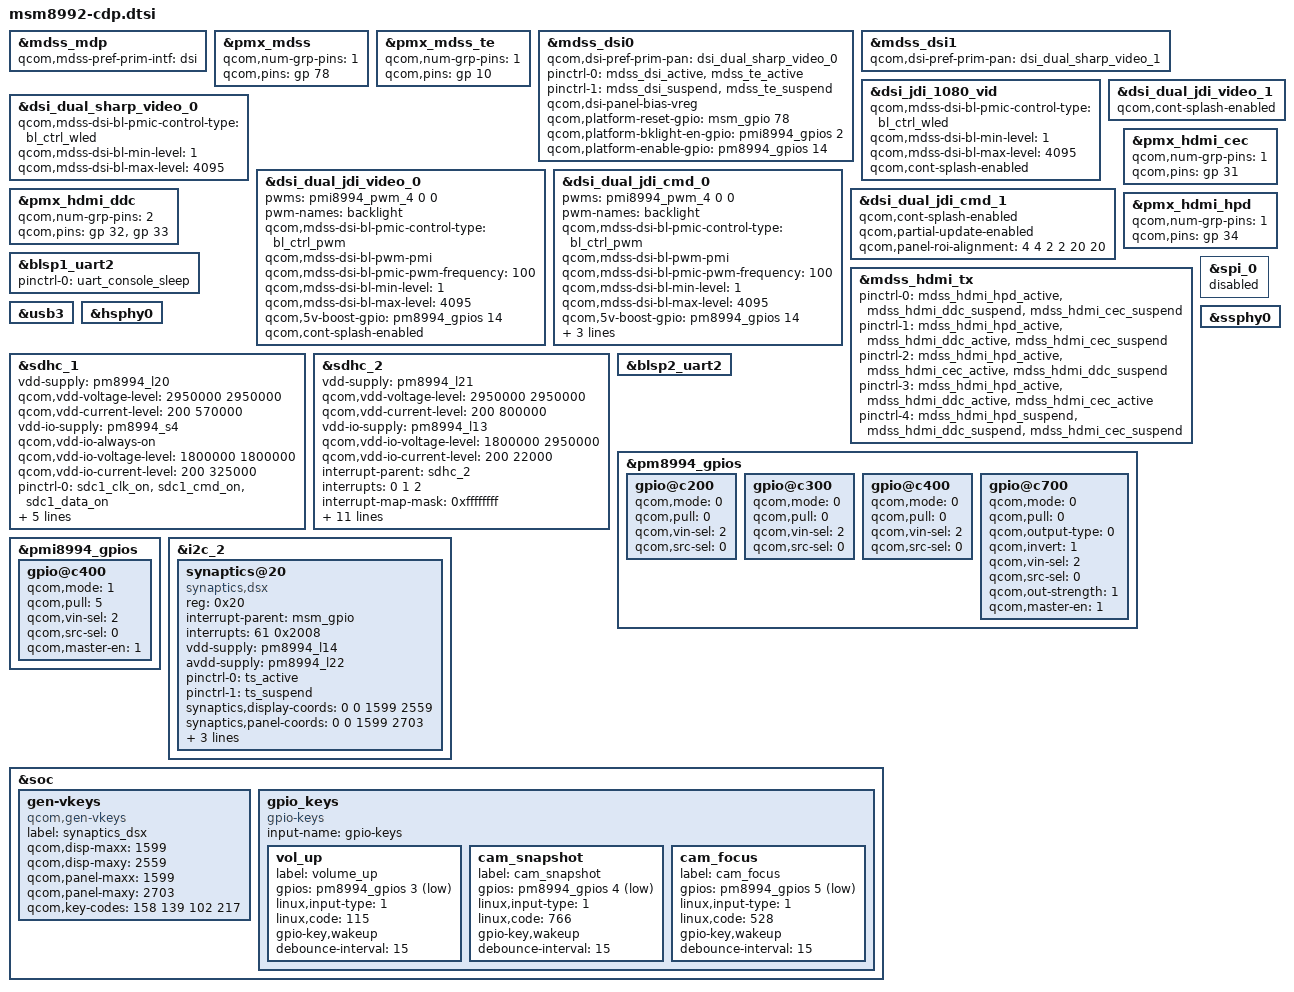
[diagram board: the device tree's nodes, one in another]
/* Copyright (c) 2014, The Linux Foundation. All rights reserved.
 *
 * This program is free software; you can redistribute it and/or modify
 * it under the terms of the GNU General Public License version 2 and
 * only version 2 as published by the Free Software Foundation.
 *
 * This program is distributed in the hope that it will be useful,
 * but WITHOUT ANY WARRANTY; without even the implied warranty of
 * MERCHANTABILITY or FITNESS FOR A PARTICULAR PURPOSE.  See the
 * GNU General Public License for more details.
 */

#include "msm8992-pinctrl.dtsi"

#include "dsi-panel-sharp-dualmipi0-wqxga-video.dtsi"
#include "dsi-panel-sharp-dualmipi1-wqxga-video.dtsi"
#include "dsi-panel-jdi-dualmipi0-video.dtsi"
#include "dsi-panel-jdi-dualmipi1-video.dtsi"
#include "dsi-panel-jdi-dualmipi0-cmd.dtsi"
#include "dsi-panel-jdi-dualmipi1-cmd.dtsi"
#include "dsi-panel-nt35597-wqxga-video.dtsi"
#include "dsi-panel-nt35597-wqxga-cmd.dtsi"
#include "dsi-panel-jdi-1080p-video.dtsi"

&mdss_mdp {
	qcom,mdss-pref-prim-intf = "dsi";
};

&pmx_mdss {
	qcom,num-grp-pins = <1>;
	qcom,pins = <&gp 78>;
};

&pmx_mdss_te {
	qcom,num-grp-pins = <1>;
	qcom,pins = <&gp 10>;
};

&mdss_dsi0 {
	qcom,dsi-pref-prim-pan = <&dsi_dual_sharp_video_0>;
	pinctrl-names = "mdss_default", "mdss_sleep";
	pinctrl-0 = <&mdss_dsi_active &mdss_te_active>;
	pinctrl-1 = <&mdss_dsi_suspend &mdss_te_suspend>;
	qcom,dsi-panel-bias-vreg;
	qcom,platform-reset-gpio = <&msm_gpio 78 0>;
	qcom,platform-bklight-en-gpio = <&pmi8994_gpios 2 0>;
	qcom,platform-enable-gpio = <&pm8994_gpios 14 0>;
};

&mdss_dsi1 {
	qcom,dsi-pref-prim-pan = <&dsi_dual_sharp_video_1>;
};

&dsi_jdi_1080_vid {
	qcom,mdss-dsi-bl-pmic-control-type = "bl_ctrl_wled";
	qcom,mdss-dsi-bl-min-level = <1>;
	qcom,mdss-dsi-bl-max-level = <4095>;
	qcom,cont-splash-enabled;
};

&dsi_dual_sharp_video_0 {
	qcom,mdss-dsi-bl-pmic-control-type = "bl_ctrl_wled";
	qcom,mdss-dsi-bl-min-level = <1>;
	qcom,mdss-dsi-bl-max-level = <4095>;
};

&dsi_dual_jdi_video_0 {
	pwms = <&pmi8994_pwm_4 0 0>;
	pwm-names = "backlight";
	qcom,mdss-dsi-bl-pmic-control-type = "bl_ctrl_pwm";
	qcom,mdss-dsi-bl-pwm-pmi;
	qcom,mdss-dsi-bl-pmic-pwm-frequency = <100>;
	qcom,mdss-dsi-bl-min-level = <1>;
	qcom,mdss-dsi-bl-max-level = <4095>;
	qcom,5v-boost-gpio = <&pm8994_gpios 14 0>;
	qcom,cont-splash-enabled;
};

&dsi_dual_jdi_video_1 {
	qcom,cont-splash-enabled;
};

&dsi_dual_jdi_cmd_0 {
	pwms = <&pmi8994_pwm_4 0 0>;
	pwm-names = "backlight";
	qcom,mdss-dsi-bl-pmic-control-type = "bl_ctrl_pwm";
	qcom,mdss-dsi-bl-pwm-pmi;
	qcom,mdss-dsi-bl-pmic-pwm-frequency = <100>;
	qcom,mdss-dsi-bl-min-level = <1>;
	qcom,mdss-dsi-bl-max-level = <4095>;
	qcom,5v-boost-gpio = <&pm8994_gpios 14 0>;
	qcom,cont-splash-enabled;
	qcom,partial-update-enabled;
	qcom,panel-roi-alignment = <4 4 2 2 20 20>;
};

&dsi_dual_jdi_cmd_1 {
	qcom,cont-splash-enabled;
	qcom,partial-update-enabled;
	qcom,panel-roi-alignment = <4 4 2 2 20 20>;
};

&pmx_hdmi_cec {
	qcom,num-grp-pins = <1>;
	qcom,pins = <&gp 31>;
};

&pmx_hdmi_ddc {
	qcom,num-grp-pins = <2>;
	qcom,pins = <&gp 32>, <&gp 33>;
};

&pmx_hdmi_hpd {
	qcom,num-grp-pins = <1>;
	qcom,pins = <&gp 34>;
};

&mdss_hdmi_tx {
	pinctrl-names = "hdmi_hpd_active", "hdmi_ddc_active",
				"hdmi_cec_active", "hdmi_active",
				"hdmi_sleep";
	pinctrl-0 = <&mdss_hdmi_hpd_active &mdss_hdmi_ddc_suspend
						&mdss_hdmi_cec_suspend>;
	pinctrl-1 = <&mdss_hdmi_hpd_active &mdss_hdmi_ddc_active
						&mdss_hdmi_cec_suspend>;
	pinctrl-2 = <&mdss_hdmi_hpd_active &mdss_hdmi_cec_active
						&mdss_hdmi_ddc_suspend>;
	pinctrl-3 = <&mdss_hdmi_hpd_active &mdss_hdmi_ddc_active
						&mdss_hdmi_cec_active>;
	pinctrl-4 = <&mdss_hdmi_hpd_suspend &mdss_hdmi_ddc_suspend
						&mdss_hdmi_cec_suspend>;
};
&blsp1_uart2 {
	status= "ok";
	pinctrl-names = "default";
	pinctrl-0 = <&uart_console_sleep>;
};

&spi_0 {
	status = "disabled";
};

&usb3 {
	status = "ok";
};

&hsphy0 {
	status = "ok";
};

&ssphy0 {
	status = "ok";
};

&sdhc_1 {
	vdd-supply = <&pm8994_l20>;
	qcom,vdd-voltage-level = <2950000 2950000>;
	qcom,vdd-current-level = <200 570000>;

	vdd-io-supply = <&pm8994_s4>;
	qcom,vdd-io-always-on;
	qcom,vdd-io-voltage-level = <1800000 1800000>;
	qcom,vdd-io-current-level = <200 325000>;

	pinctrl-names = "active", "sleep";
	pinctrl-0 = <&sdc1_clk_on &sdc1_cmd_on &sdc1_data_on>;
	pinctrl-1 = <&sdc1_clk_off &sdc1_cmd_off &sdc1_data_off>;

	qcom,clk-rates = <400000 20000000 25000000 50000000>;
	qcom,nonremovable;
	status = "ok";
};

&sdhc_2 {
	vdd-supply = <&pm8994_l21>;
	qcom,vdd-voltage-level = <2950000 2950000>;
	qcom,vdd-current-level = <200 800000>;

	vdd-io-supply = <&pm8994_l13>;
	qcom,vdd-io-voltage-level = <1800000 2950000>;
	qcom,vdd-io-current-level = <200 22000>;

	#address-cells = <0>;
	interrupt-parent = <&sdhc_2>;
	interrupts = <0 1 2>;
	#interrupt-cells = <1>;
	interrupt-map-mask = <0xffffffff>;
	interrupt-map = <0 &intc 0 125 0
			1 &intc 0 221 0
			2 &pm8994_gpios 8 0x3>;
	interrupt-names = "hc_irq", "pwr_irq", "status_irq";
	cd-gpios = <&pm8994_gpios 8 0x1>;

	pinctrl-names = "active", "sleep";
	pinctrl-0 = <&sdc2_clk_on &sdc2_cmd_on &sdc2_data_on>;
	pinctrl-1 = <&sdc2_clk_off &sdc2_cmd_off &sdc2_data_off>;

	qcom,clk-rates = <400000 20000000 25000000 50000000 100000000 200000000>;
	qcom,bus-speed-mode = "SDR12", "SDR25", "SDR50", "DDR50", "SDR104";
	status = "ok";
};

&blsp2_uart2 {
	status = "ok";
};

&pm8994_gpios {
	gpio@c200 { /* GPIO 3 */
		qcom,mode = <0>;		/* Digital in */
		qcom,pull = <0>;		/* PULL up 30uA */
		qcom,vin-sel = <2>;		/* Logical 1 voltage value 1.8v */
		qcom,src-sel = <0>;		/* Constant */
		status = "okay";
	};

	gpio@c300 { /* GPIO 4 */
		qcom,mode = <0>;		/* Digital in */
		qcom,pull = <0>;		/* PULL up 30uA */
		qcom,vin-sel = <2>;		/* Logical 1 voltage value 1.8v */
		qcom,src-sel = <0>;		/* Constant */
		status = "okay";
	};

	gpio@c400 { /* GPIO 5 */
		qcom,mode = <0>;		/* Digital in */
		qcom,pull = <0>;		/* PULL up 30uA */
		qcom,vin-sel = <2>;		/* Logical 1 voltage value 1.8v */
		qcom,src-sel = <0>;		/* Constant */
		status = "okay";
	};

	gpio@c700 { /* GPIO 8 */
		qcom,mode = <0>;                /* Digital in */
		qcom,pull = <0>;                /* PULL up 30uA */
		qcom,output-type = <0>;         /* CMOS logic */
		qcom,invert = <1>;              /* Output high */
		qcom,vin-sel = <2>;             /* Logical 1 voltage value 1.8v */
		qcom,src-sel = <0>;             /* Constant */
		qcom,out-strength = <1>;        /* Low drive strength */
		qcom,master-en = <1>;           /* Enable GPIO */
		status = "okay";
	};
};

&pmi8994_gpios {
	gpio@c400 {	/* GPIO 5  OTG SWITCH EN */
		qcom,mode = <1>;	/* DIGITAL OUT */
		qcom,pull = <5>;	/* No Pull */
		qcom,vin-sel = <2>;	/* 1.8 */
		qcom,src-sel = <0>;	/* GPIO */
		qcom,master-en = <1>;	/* ENABLE GPIO */
		status = "okay";
	};
};

&i2c_2 {
	synaptics@20 {
		compatible = "synaptics,dsx";
		reg = <0x20>;
		interrupt-parent = <&msm_gpio>;
		interrupts = <61 0x2008>;
		vdd-supply = <&pm8994_l14>;
		avdd-supply = <&pm8994_l22>;
		pinctrl-names = "pmx_ts_active", "pmx_ts_suspend";
		pinctrl-0 = <&ts_active>;
		pinctrl-1 = <&ts_suspend>;
		synaptics,display-coords = <0 0 1599 2559>;
		synaptics,panel-coords = <0 0 1599 2703>;
		synaptics,reset-gpio = <&msm_gpio 60 0x00>;
		synaptics,irq-gpio = <&msm_gpio 61 0x00>;
		synaptics,disable-gpios;
	};
};

&soc {
	gen-vkeys {
		compatible = "qcom,gen-vkeys";
		label = "synaptics_dsx";
		qcom,disp-maxx = <1599>;
		qcom,disp-maxy = <2559>;
		qcom,panel-maxx = <1599>;
		qcom,panel-maxy = <2703>;
		qcom,key-codes = <158 139 102 217>;
	};

	gpio_keys {
		compatible = "gpio-keys";
		input-name = "gpio-keys";

		vol_up {
			label = "volume_up";
			gpios = <&pm8994_gpios 3 0x1>;
			linux,input-type = <1>;
			linux,code = <115>;
			gpio-key,wakeup;
			debounce-interval = <15>;
		};

		cam_snapshot {
			label = "cam_snapshot";
			gpios = <&pm8994_gpios 4 0x1>;
			linux,input-type = <1>;
			linux,code = <766>;
			gpio-key,wakeup;
			debounce-interval = <15>;
		};

		cam_focus {
			label = "cam_focus";
			gpios = <&pm8994_gpios 5 0x1>;
			linux,input-type = <1>;
			linux,code = <528>;
			gpio-key,wakeup;
			debounce-interval = <15>;
		};
	};
};
